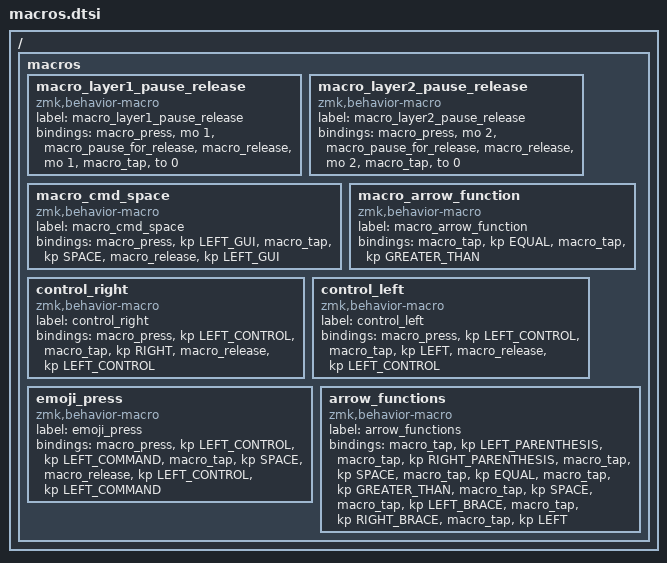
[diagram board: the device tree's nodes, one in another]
/ {
    macros {
        macro_layer1_pause_release: macro_layer1_pause_release {
        compatible = "zmk,behavior-macro";
        label = "macro_layer1_pause_release";
        #binding-cells = <0>;
        bindings =
            <&macro_press>,
            <&mo 1>,
            <&macro_pause_for_release>,
            <&macro_release>,
            <&mo 1>,
            <&macro_tap>,
            <&to 0>;
    };

    macro_layer2_pause_release: macro_layer2_pause_release {
        compatible = "zmk,behavior-macro";
        label = "macro_layer2_pause_release";
        #binding-cells = <0>;
        bindings =
            <&macro_press>,
            <&mo 2>,
            <&macro_pause_for_release>,
            <&macro_release>,
            <&mo 2>,
            <&macro_tap>,
            <&to 0>;
    };

    macro_cmd_space: macro_cmd_space {
        compatible = "zmk,behavior-macro";
        label = "macro_cmd_space";
        #binding-cells = <0>;
        bindings =
            <&macro_press>,
            <&kp LEFT_GUI>,
            <&macro_tap>,
            <&kp SPACE>,
            <&macro_release>,
            <&kp LEFT_GUI>;
    };

    macro_arrow_function: macro_arrow_function {
        compatible = "zmk,behavior-macro";
        label = "macro_arrow_function";
        #binding-cells = <0>;
        bindings =
            <&macro_tap>,
            <&kp EQUAL>,
            <&macro_tap>,
            <&kp GREATER_THAN>;
    };

    control_right: control_right {
        compatible = "zmk,behavior-macro";
        label = "control_right";
        #binding-cells = <0>;
        bindings =
            <&macro_press>,
            <&kp LEFT_CONTROL>,
            <&macro_tap>,
            <&kp RIGHT>,
            <&macro_release>,
            <&kp LEFT_CONTROL>;
    };

    control_left: control_left {
        compatible = "zmk,behavior-macro";
        label = "control_left";
        #binding-cells = <0>;
        bindings =
            <&macro_press>,
            <&kp LEFT_CONTROL>,
            <&macro_tap>,
            <&kp LEFT>,
            <&macro_release>,
            <&kp LEFT_CONTROL>;
    };

    emoji_press: emoji_press {
        compatible = "zmk,behavior-macro";
        label = "emoji_press";
        #binding-cells = <0>;
        bindings =
            <&macro_press>,
            <&kp LEFT_CONTROL &kp LEFT_COMMAND>,
            <&macro_tap>,
            <&kp SPACE>,
            <&macro_release>,
            <&kp LEFT_CONTROL &kp LEFT_COMMAND>;
    };

    arrow_functions: arrow_functions {
        compatible = "zmk,behavior-macro";
        label = "arrow_functions";
        #binding-cells = <0>;
        bindings =
            <&macro_tap>,
            <&kp LEFT_PARENTHESIS>,
            <&macro_tap>,
            <&kp RIGHT_PARENTHESIS>,
            <&macro_tap>,
            <&kp SPACE>,
            <&macro_tap>,
            <&kp EQUAL>,
            <&macro_tap>,
            <&kp GREATER_THAN>,
            <&macro_tap>,
            <&kp SPACE>,
            <&macro_tap>,
            <&kp LEFT_BRACE>,
            <&macro_tap>,
            <&kp RIGHT_BRACE>,
            <&macro_tap>,
            <&kp LEFT>;
        };
    };
};

